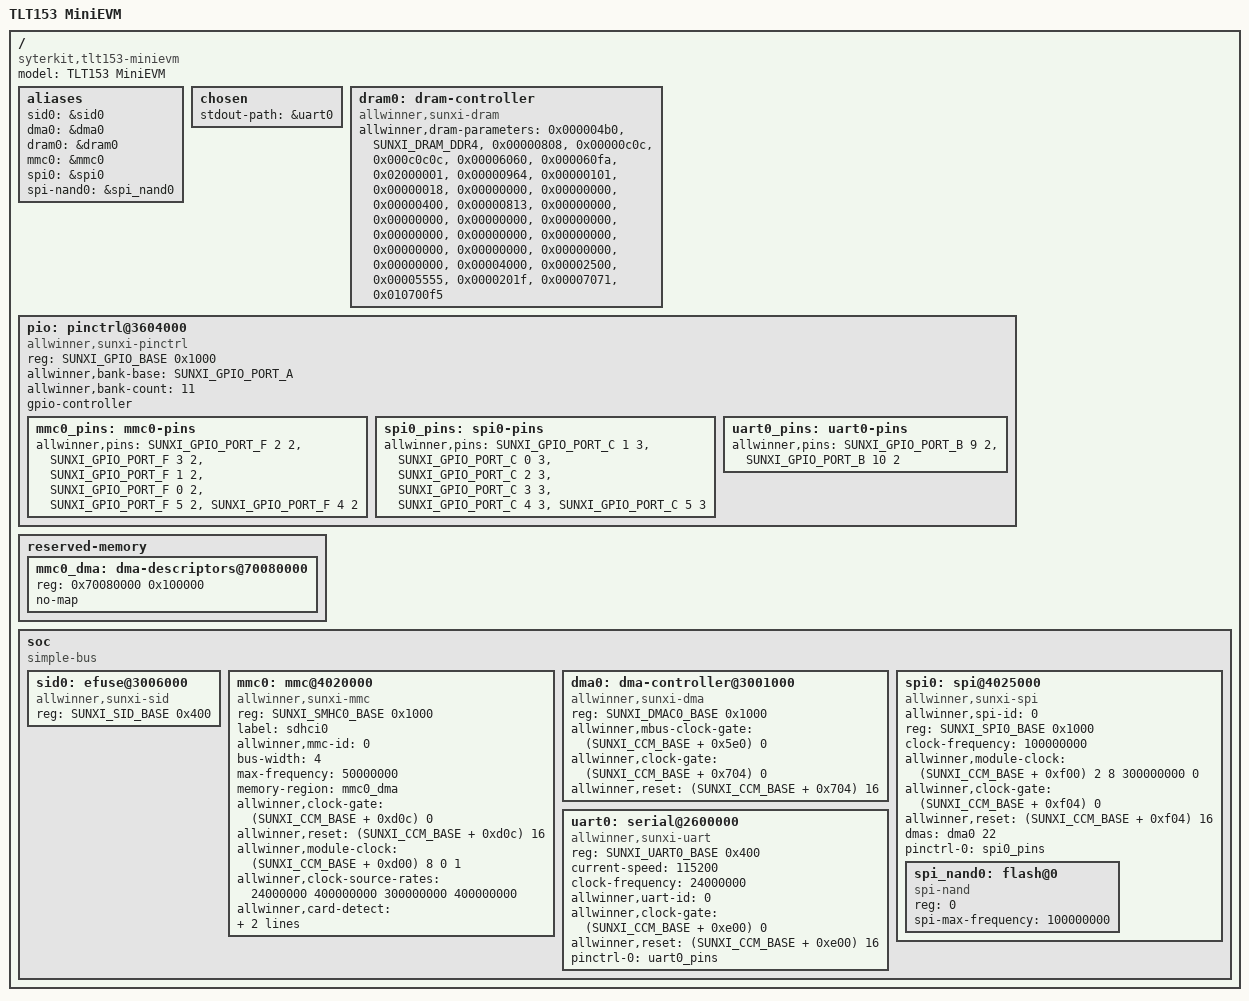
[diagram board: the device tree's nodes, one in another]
// SPDX-License-Identifier: GPL-2.0+
/dts-v1/;

#include <dt-bindings/dram/dram-param.h>

#include <dt-bindings/gpio/sunxi-gpio.h>
#include <dt-bindings/soc/sun8iw22.h>

/ {
	#address-cells = <1>;
	#size-cells = <1>;
	model = "TLT153 MiniEVM";
	compatible = "syterkit,tlt153-minievm";

	aliases {
		sid0 = &sid0;
		dma0 = &dma0;
		dram0 = &dram0;
		mmc0 = &mmc0;
		spi0 = &spi0;
		spi-nand0 = &spi_nand0;
	};

	chosen {
		stdout-path = &uart0;
	};

	dram0: dram-controller {
		compatible = "allwinner,sunxi-dram";
		allwinner,dram-parameters =
			<0x000004b0>,
			<SUNXI_DRAM_DDR4>,
			<0x00000808>,
			<0x00000c0c>,
			<0x000c0c0c>,
			<0x00006060>,
			<0x000060fa>,
			<0x02000001>,
			<0x00000964>,
			<0x00000101>,
			<0x00000018>,
			<0x00000000>,
			<0x00000000>,
			<0x00000400>,
			<0x00000813>,
			<0x00000000>,
			<0x00000000>,
			<0x00000000>,
			<0x00000000>,
			<0x00000000>,
			<0x00000000>,
			<0x00000000>,
			<0x00000000>,
			<0x00000000>,
			<0x00000000>,
			<0x00000000>,
			<0x00004000>,
			<0x00002500>,
			<0x00005555>,
			<0x0000201f>,
			<0x00007071>,
			<0x010700f5>;
		status = "okay";
	};

	pio: pinctrl@3604000 {
		compatible = "allwinner,sunxi-pinctrl";
		reg = <SUNXI_GPIO_BASE 0x1000>;
		allwinner,bank-base = <SUNXI_GPIO_PORT_A>;
		allwinner,bank-count = <11>;
		gpio-controller;
		#gpio-cells = <3>;

		mmc0_pins: mmc0-pins {
			allwinner,pins =
				<SUNXI_GPIO_PORT_F 2 2>,
				<SUNXI_GPIO_PORT_F 3 2>,
				<SUNXI_GPIO_PORT_F 1 2>,
				<SUNXI_GPIO_PORT_F 0 2>,
				<SUNXI_GPIO_PORT_F 5 2>,
				<SUNXI_GPIO_PORT_F 4 2>;
		};

		spi0_pins: spi0-pins {
			allwinner,pins =
				<SUNXI_GPIO_PORT_C 1 3>,
				<SUNXI_GPIO_PORT_C 0 3>,
				<SUNXI_GPIO_PORT_C 2 3>,
				<SUNXI_GPIO_PORT_C 3 3>,
				<SUNXI_GPIO_PORT_C 4 3>,
				<SUNXI_GPIO_PORT_C 5 3>;
		};

		uart0_pins: uart0-pins {
			allwinner,pins =
				<SUNXI_GPIO_PORT_B 9 2>,
				<SUNXI_GPIO_PORT_B 10 2>;
		};
	};

	reserved-memory {
		#address-cells = <1>;
		#size-cells = <1>;
		ranges;

		mmc0_dma: dma-descriptors@70080000 {
			reg = <0x70080000 0x100000>;
			no-map;
		};
	};

	soc {
		compatible = "simple-bus";
		#address-cells = <1>;
		#size-cells = <1>;
		ranges;

		sid0: efuse@3006000 {
			compatible = "allwinner,sunxi-sid";
			reg = <SUNXI_SID_BASE 0x400>;
			status = "okay";
		};

		mmc0: mmc@4020000 {
			compatible = "allwinner,sunxi-mmc";
			reg = <SUNXI_SMHC0_BASE 0x1000>;
			label = "sdhci0";
			allwinner,mmc-id = <0>;
			bus-width = <4>;
			max-frequency = <50000000>;
			memory-region = <&mmc0_dma>;
			allwinner,clock-gate = <(SUNXI_CCM_BASE + 0xd0c) 0>;
			allwinner,reset = <(SUNXI_CCM_BASE + 0xd0c) 16>;
			allwinner,module-clock =
				<(SUNXI_CCM_BASE + 0xd00) 8 0 1>;
			allwinner,clock-source-rates =
				<24000000 400000000 300000000 400000000>;
			allwinner,card-detect =
				<&pio SUNXI_GPIO_PORT_F 6 0 0>;
			pinctrl-names = "default";
			pinctrl-0 = <&mmc0_pins>;
			status = "okay";
		};

		dma0: dma-controller@3001000 {
			compatible = "allwinner,sunxi-dma";
			reg = <SUNXI_DMAC0_BASE 0x1000>;
			#dma-cells = <1>;
			allwinner,mbus-clock-gate = <(SUNXI_CCM_BASE + 0x5e0) 0>;
			allwinner,clock-gate = <(SUNXI_CCM_BASE + 0x704) 0>;
			allwinner,reset = <(SUNXI_CCM_BASE + 0x704) 16>;
			status = "okay";
		};

		spi0: spi@4025000 {
			compatible = "allwinner,sunxi-spi";
			#address-cells = <1>;
			#size-cells = <0>;
			allwinner,spi-id = <0>;
			reg = <SUNXI_SPI0_BASE 0x1000>;
			clock-frequency = <100000000>;
			allwinner,module-clock = <(SUNXI_CCM_BASE + 0xf00) 2 8 300000000 0>;
			allwinner,clock-gate = <(SUNXI_CCM_BASE + 0xf04) 0>;
			allwinner,reset = <(SUNXI_CCM_BASE + 0xf04) 16>;
			dmas = <&dma0 22>;
			dma-names = "rx";
			pinctrl-names = "default";
			pinctrl-0 = <&spi0_pins>;
			status = "okay";

			spi_nand0: flash@0 {
				compatible = "spi-nand";
				reg = <0>;
				spi-max-frequency = <100000000>;
			};
		};

		uart0: serial@2600000 {
			compatible = "allwinner,sunxi-uart";
			reg = <SUNXI_UART0_BASE 0x400>;
			current-speed = <115200>;
			clock-frequency = <24000000>;
			allwinner,uart-id = <0>;
			allwinner,clock-gate = <(SUNXI_CCM_BASE + 0xe00) 0>;
			allwinner,reset = <(SUNXI_CCM_BASE + 0xe00) 16>;
			pinctrl-names = "default";
			pinctrl-0 = <&uart0_pins>;
			status = "okay";
		};
	};
};
